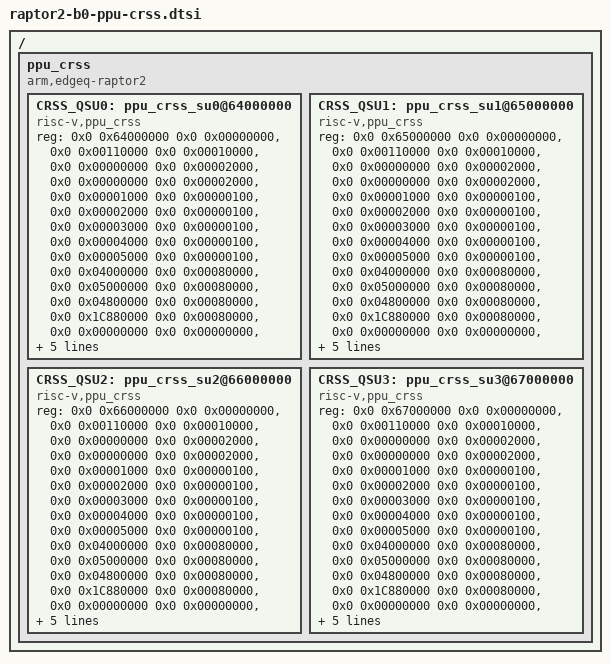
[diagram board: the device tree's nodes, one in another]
// SPDX-License-Identifier: GPL-2.0
/*
 * EdgeQ Inc.
 *
 * EdgeQ Raptor2 PPU_CRSS DTSI
 */

/ {

	ppu_crss {
		compatible = "arm,edgeq-raptor2";
		#address-cells = <2>;
		#size-cells = <2>;

		CRSS_QSU0: ppu_crss_su0@64000000 {
			compatible = "risc-v,ppu_crss";
			device_type = "su";
			#address-cells = <2>;
			#size-cells = <2>;
			ranges;
			reg =	<0x0 0x64000000 0x0 0x00000000>,
				<0x0 0x00110000 0x0 0x00010000>,
				<0x0 0x00000000 0x0 0x00002000>,
				<0x0 0x00000000 0x0 0x00002000>,
				<0x0 0x00001000 0x0 0x00000100>,
				<0x0 0x00002000 0x0 0x00000100>,
				<0x0 0x00003000 0x0 0x00000100>,
				<0x0 0x00004000 0x0 0x00000100>,
				<0x0 0x00005000 0x0 0x00000100>,
				<0x0 0x04000000 0x0 0x00080000>,
				<0x0 0x05000000 0x0 0x00080000>,
				<0x0 0x04800000 0x0 0x00080000>,
				<0x0 0x1C880000 0x0 0x00080000>,
				<0x0 0x00000000 0x0 0x00000000>,
				<0x0 0x00000000 0x0 0x00004000>,
				<0x0 0x00080000 0x0 0x00008000>;
			reg-names = "sudev_base", "cpu", "d-cache", "i-cache", "suinfo_offset",
				"suconf_offset", "suau_offset", "sustats_offset", "sudbg_offset",
				"lmem_addr_local_wb", "lmem_addr_local_unc", "lmem_addr_local_wt",
				"lmem_e1", "lmem_e1_b2", "ilmoffs", "dlmoffs";
			enable-method = "reset-vector";
			sudev = <&SUDEV>;
			sumem = <&SUMEM>;
			status = "okay";
		};

		CRSS_QSU1: ppu_crss_su1@65000000 {
			compatible = "risc-v,ppu_crss";
			device_type = "su";
			#address-cells = <2>;
			#size-cells = <2>;
			ranges;
			reg =	<0x0 0x65000000 0x0 0x00000000>,
				<0x0 0x00110000 0x0 0x00010000>,
				<0x0 0x00000000 0x0 0x00002000>,
				<0x0 0x00000000 0x0 0x00002000>,
				<0x0 0x00001000 0x0 0x00000100>,
				<0x0 0x00002000 0x0 0x00000100>,
				<0x0 0x00003000 0x0 0x00000100>,
				<0x0 0x00004000 0x0 0x00000100>,
				<0x0 0x00005000 0x0 0x00000100>,
				<0x0 0x04000000 0x0 0x00080000>,
				<0x0 0x05000000 0x0 0x00080000>,
				<0x0 0x04800000 0x0 0x00080000>,
				<0x0 0x1C880000 0x0 0x00080000>,
				<0x0 0x00000000 0x0 0x00000000>,
				<0x0 0x00000000 0x0 0x00004000>,
				<0x0 0x00080000 0x0 0x00008000>;
			reg-names = "sudev_base", "cpu", "d-cache", "i-cache", "suinfo_offset",
				"suconf_offset", "suau_offset", "sustats_offset", "sudbg_offset",
				"lmem_addr_local_wb", "lmem_addr_local_unc", "lmem_addr_local_wt",
				"lmem_e1", "lmem_e1_b2", "ilmoffs", "dlmoffs";
			enable-method = "reset-vector";
			sudev = <&SUDEV>;
			sumem = <&SUMEM>;
			status = "okay";
		};

		CRSS_QSU2: ppu_crss_su2@66000000 {
			compatible = "risc-v,ppu_crss";
			device_type = "su";
			#address-cells = <2>;
			#size-cells = <2>;
			ranges;
			reg =	<0x0 0x66000000 0x0 0x00000000>,
				<0x0 0x00110000 0x0 0x00010000>,
				<0x0 0x00000000 0x0 0x00002000>,
				<0x0 0x00000000 0x0 0x00002000>,
				<0x0 0x00001000 0x0 0x00000100>,
				<0x0 0x00002000 0x0 0x00000100>,
				<0x0 0x00003000 0x0 0x00000100>,
				<0x0 0x00004000 0x0 0x00000100>,
				<0x0 0x00005000 0x0 0x00000100>,
				<0x0 0x04000000 0x0 0x00080000>,
				<0x0 0x05000000 0x0 0x00080000>,
				<0x0 0x04800000 0x0 0x00080000>,
				<0x0 0x1C880000 0x0 0x00080000>,
				<0x0 0x00000000 0x0 0x00000000>,
				<0x0 0x00000000 0x0 0x00004000>,
				<0x0 0x00080000 0x0 0x00008000>;
			reg-names = "sudev_base", "cpu", "d-cache", "i-cache", "suinfo_offset",
				"suconf_offset", "suau_offset", "sustats_offset", "sudbg_offset",
				"lmem_addr_local_wb", "lmem_addr_local_unc", "lmem_addr_local_wt",
				"lmem_e1", "lmem_e1_b2", "ilmoffs", "dlmoffs";
			enable-method = "reset-vector";
			sudev = <&SUDEV>;
			sumem = <&SUMEM>;
			status = "okay";
		};

		CRSS_QSU3: ppu_crss_su3@67000000 {
			compatible = "risc-v,ppu_crss";
			device_type = "su";
			#address-cells = <2>;
			#size-cells = <2>;
			ranges;
			reg =	<0x0 0x67000000 0x0 0x00000000>,
				<0x0 0x00110000 0x0 0x00010000>,
				<0x0 0x00000000 0x0 0x00002000>,
				<0x0 0x00000000 0x0 0x00002000>,
				<0x0 0x00001000 0x0 0x00000100>,
				<0x0 0x00002000 0x0 0x00000100>,
				<0x0 0x00003000 0x0 0x00000100>,
				<0x0 0x00004000 0x0 0x00000100>,
				<0x0 0x00005000 0x0 0x00000100>,
				<0x0 0x04000000 0x0 0x00080000>,
				<0x0 0x05000000 0x0 0x00080000>,
				<0x0 0x04800000 0x0 0x00080000>,
				<0x0 0x1C880000 0x0 0x00080000>,
				<0x0 0x00000000 0x0 0x00000000>,
				<0x0 0x00000000 0x0 0x00004000>,
				<0x0 0x00080000 0x0 0x00008000>;
			reg-names = "sudev_base", "cpu", "d-cache", "i-cache", "suinfo_offset",
				"suconf_offset", "suau_offset", "sustats_offset", "sudbg_offset",
				"lmem_addr_local_wb", "lmem_addr_local_unc", "lmem_addr_local_wt",
				"lmem_e1", "lmem_e1_b2", "ilmoffs", "dlmoffs";
			enable-method = "reset-vector";
			sudev = <&SUDEV>;
			sumem = <&SUMEM>;
			status = "okay";
		};
	};
};
